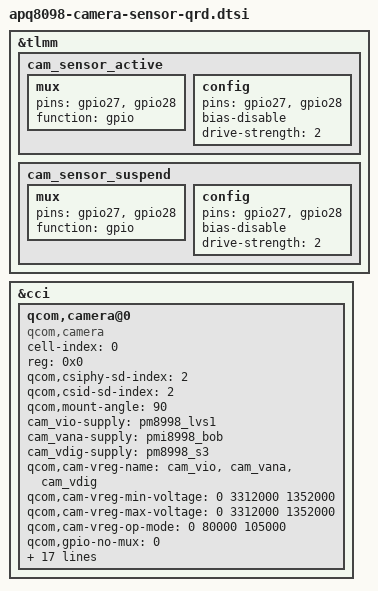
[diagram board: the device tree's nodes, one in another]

/*
 * Copyright (c) 2016, The Linux Foundation. All rights reserved.
 *
 * This program is free software; you can redistribute it and/or modify
 * it under the terms of the GNU General Public License version 2 and
 * only version 2 as published by the Free Software Foundation.
 *
 * This program is distributed in the hope that it will be useful,
 * but WITHOUT ANY WARRANTY; without even the implied warranty of
 * MERCHANTABILITY or FITNESS FOR A PARTICULAR PURPOSE.  See the
 * GNU General Public License for more details.
 */
 &tlmm {
 		cam_sensor_active: cam_sensor_active {
			mux {
				pins = "gpio27", "gpio28";
				function = "gpio";
			};

			config {
				pins = "gpio27", "gpio28";
				bias-disable; /* No PULL */
				drive-strength = <2>; /* 2 MA */
			};
		};
 
		cam_sensor_suspend: cam_sensor_suspend {
			mux {
				pins = "gpio27", "gpio28";
				function = "gpio";
			};

			config {
				pins = "gpio27", "gpio28";
				bias-disable; /* No PULL */
				drive-strength = <2>; /* 2 MA */
			};
		};
 };
 
&cci {
	qcom,camera@0 {
		cell-index = <0>;
		compatible = "qcom,camera";
		reg = <0x0>;
		qcom,csiphy-sd-index = <2>;
		qcom,csid-sd-index = <2>;
		qcom,mount-angle = <90>;
		cam_vio-supply = <&pm8998_lvs1>;
		cam_vana-supply = <&pmi8998_bob>;
		cam_vdig-supply = <&pm8998_s3>;
		qcom,cam-vreg-name = "cam_vio", "cam_vana", "cam_vdig";
		qcom,cam-vreg-min-voltage = <0 3312000 1352000>;
		qcom,cam-vreg-max-voltage = <0 3312000 1352000>;
		qcom,cam-vreg-op-mode = <0 80000 105000>;
		qcom,gpio-no-mux = <0>;
		pinctrl-names = "cam_default", "cam_suspend";
		pinctrl-0 = <&cam_sensor_mclk1_active &cam_sensor_active>;
		pinctrl-1 = <&cam_sensor_mclk1_suspend &cam_sensor_suspend>;
		gpios = <&tlmm 14 0>,
						<&tlmm 27 0>,
						<&tlmm 28 0>;
		qcom,gpio-standby = <1>;
		qcom,gpio-reset = <2>;
		qcom,gpio-req-tbl-num = <0 1 2>;
		qcom,gpio-req-tbl-flags = <1 0 0>;
		qcom,gpio-req-tbl-label = "CAMIF_MCLK1",
					"CAM_STANDBY",
					"CAM_RESET0";
		qcom,sensor-position = <0>;
		qcom,sensor-mode = <0>;
		qcom,cci-master = <1>;
		status = "ok";
		clocks = <&clock_mmss clk_mclk1_clk_src>,
				<&clock_mmss clk_mmss_camss_mclk1_clk>;
		clock-names = "cam_src_clk", "cam_clk";
		qcom,clock-rates = <24000000 0>;
	};
};
